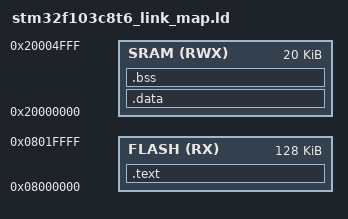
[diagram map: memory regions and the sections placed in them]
MEMORY
{
	/* Флэш память с возможностью чтения (R) и выполнения (X) кода
	Адрес начала флеш памяти 0x08000000
	Размер флэш памяти 128kb (0x20000) */
	FLASH (RX) : ORIGIN = 0x08000000, LENGTH = 0x20000
	
	/* RAM память возможностью чтения (R), записи (W) и выполнения (X) кода (0x5000 - 20kb) */
	SRAM (RWX) : ORIGIN = 0x20000000, LENGTH = 0x5000
}

SECTIONS
{
	/* Собираем секции .text из всех входных файлов ( *(.text) ) 
	и направляем их в секцию .text выходного файла, 
	которую в свою очередь записываем во флэш память */ 
	.text :
	{
		*(.text);
	} > FLASH	
	
	. = ALIGN(4);
	
	_data_flash = .;	/* Записываем в переменную адрес начала сегмента данных во FLASH памяти */
	
	.data : AT(_data_flash)
	{
		_sdata = .;		/* Записываем в переменную адрес начала сегмента данных в SRAM памяти */
		
		*(.data)
		
		. = ALIGN(4);
		
		_edata = .;		/* Записываем в переменную адрес конца сегмента данных в SRAM памяти */	
	} > SRAM
	
	.bss :
	{
		*(.bss)
		. = ALIGN(4);
	} > SRAM
}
